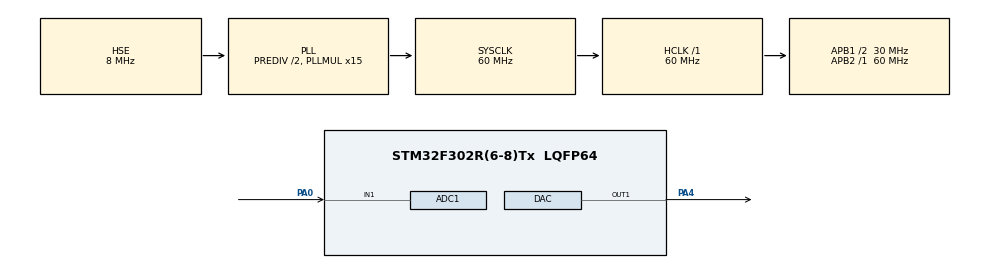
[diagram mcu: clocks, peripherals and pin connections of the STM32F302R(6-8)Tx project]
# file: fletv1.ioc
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ADC1.Channel-1\#ChannelRegularConversion=ADC_CHANNEL_1
ADC1.ClockPrescaler=ADC_CLOCK_ASYNC_DIV1
ADC1.ContinuousConvMode=ENABLE
ADC1.NbrOfConversionFlag=1
ADC1.Offset-1\#ChannelRegularConversion=0
ADC1.OffsetNumber-1\#ChannelRegularConversion=ADC_OFFSET_NONE
ADC1.Rank-1\#ChannelRegularConversion=1
ADC1.Resolution=ADC_RESOLUTION_10B
ADC1.SamplingTime-1\#ChannelRegularConversion=ADC_SAMPLETIME_1CYCLE_5
ADC1.SamplingTimeOPAMP-1\#ChannelRegularConversion=ADC_SAMPLETIME_61CYCLES_5
ADC1.master=1
DAC.DAC_Trigger=DAC_TRIGGER_T2_TRGO
Dma.DAC_CH1.0.Direction=DMA_MEMORY_TO_PERIPH
Dma.DAC_CH1.0.Instance=DMA1_Channel3
Dma.DAC_CH1.0.MemDataAlignment=DMA_MDATAALIGN_WORD
Dma.DAC_CH1.0.MemInc=DMA_MINC_ENABLE
Dma.DAC_CH1.0.Mode=DMA_CIRCULAR
Dma.DAC_CH1.0.PeriphDataAlignment=DMA_PDATAALIGN_WORD
Dma.DAC_CH1.0.PeriphInc=DMA_PINC_DISABLE
Dma.DAC_CH1.0.Priority=DMA_PRIORITY_LOW
Dma.Request0=DAC_CH1
Mcu.Family=STM32F3
Mcu.Name=STM32F302R(6-8)Tx
Mcu.Package=LQFP64
NVIC.ADC1_IRQn=true\:0\:0\:false\:false\:true\:true\:true\:true
NVIC.DMA1_Channel3_IRQn=true\:0\:0\:false\:false\:true\:false\:true\:true
NVIC.PriorityGroup=NVIC_PRIORITYGROUP_0
PA0.Mode=IN1-Single-Ended
PA0.Signal=ADC1_IN1
PA4.Signal=COMP_DAC1_group
PF0-OSC_IN.Mode=HSE-External-Oscillator
PF0-OSC_IN.Signal=RCC_OSC_IN
PF1-OSC_OUT.Mode=HSE-External-Oscillator
PF1-OSC_OUT.Signal=RCC_OSC_OUT
ProjectManager.HeapSize=0x200
ProjectManager.StackSize=0x400
ProjectManager.TargetToolchain=STM32CubeIDE
RCC.ADC12PRES=RCC_ADC1PLLCLK_DIV256
RCC.AHBFreq_Value=60000000
RCC.APB1CLKDivider=RCC_HCLK_DIV2
RCC.APB1Freq_Value=30000000
RCC.APB1TimFreq_Value=60000000
RCC.APB2Freq_Value=60000000
RCC.APB2TimFreq_Value=60000000
RCC.CortexFreq_Value=60000000
RCC.HCLKFreq_Value=60000000
RCC.HSE_VALUE=8000000
RCC.HSI_VALUE=8000000
RCC.PLLM=8
RCC.PLLMUL=RCC_PLL_MUL15
RCC.PLLN=336
RCC.PLLP=RCC_PLLP_DIV4
RCC.PLLQ=7
RCC.PLLSourceVirtual=RCC_PLLSOURCE_HSE
RCC.RCC_PLLsource_Clock_Source_FROM_HSE=RCC_HSE_PREDIV_DIV2
RCC.SYSCLKFreq_VALUE=60000000
RCC.SYSCLKSourceVirtual=RCC_SYSCLKSOURCE_PLLCLK
RCC.USBFreq_Value=60000000
SH.COMP_DAC1_group.0=DAC_OUT1,DAC_OUT1
TIM2.Period=1000-1
TIM2.Prescaler=3
TIM2.TIM_MasterOutputTrigger=TIM_TRGO_UPDATE
VP_TIM2_VS_ClockSourceINT.Mode=Internal
board=NUCLEO-F302R8

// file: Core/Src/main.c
/* USER CODE BEGIN Header */
/**
  ******************************************************************************
  * @file           : main.c
  * @brief          : Main program body
  ******************************************************************************
  * @attention
  *
  * Copyright (c) 2024 STMicroelectronics.
  * All rights reserved.
  *
  * This software is licensed under terms that can be found in the LICENSE file
  * in the root directory of this software component.
  * If no LICENSE file comes with this software, it is provided AS-IS.
  *
  ******************************************************************************
  */
/* USER CODE END Header */
#include "main.h"

/* USER CODE BEGIN Includes */
#include "math.h"
/* USER CODE END Includes */

/* USER CODE BEGIN PD */
#define PI 3.1415926
#define NUM_OF_SAMPLES 1000

/* USER CODE END PD */

ADC_HandleTypeDef hadc1;

DAC_HandleTypeDef hdac;
DMA_HandleTypeDef hdma_dac_ch1;

TIM_HandleTypeDef htim2;

void SystemClock_Config(void);
static void MX_GPIO_Init(void);
static void MX_DMA_Init(void);
static void MX_DAC_Init(void);
static void MX_TIM2_Init(void);
static void MX_ADC1_Init(void);

/* USER CODE BEGIN 0 */
uint32_t sine_val[NUM_OF_SAMPLES];
uint32_t adc_read;

void HAL_TIM_PeriodElapsedCallback(TIM_HandleTypeDef *htim){
// do something cool
}

void HAL_ADC_ConvCpltCallback(ADC_HandleTypeDef* adc_address){
	static int number_of_interrupts = 0;
	if(adc_address == &hadc1){
		if(number_of_interrupts == 12000){
			number_of_interrupts = 0;
			adc_read = HAL_ADC_GetValue(&hadc1);
			if(0 < adc_read && adc_read < 1000 - 1){
				TIM2->ARR = HAL_ADC_GetValue(&hadc1) - 1;
				TIM2->CNT = 0;
		}
			else if(adc_read == 0){
				TIM2->ARR = 1;
				TIM2->CNT = 0;
			}
			else{
				TIM2->ARR = 1000 - 1;
				TIM2->CNT = 0;
			}
		}

	}
	number_of_interrupts++;
}

void get_sine(){
	  for(int i = 0; i < NUM_OF_SAMPLES; i++){
		  sine_val[i] = (sin(i*2*PI/NUM_OF_SAMPLES) +1) * ((0xFFF + 1) / 2);

	  }
}

/* USER CODE END 0 */

int main(void)
{

  /* MCU Configuration--------------------------------------------------------*/

  /* Reset of all peripherals, Initializes the Flash interface and the Systick. */
  HAL_Init();

  /* Configure the system clock */
  SystemClock_Config();

  /* Initialize all configured peripherals */
  MX_GPIO_Init();
  MX_DMA_Init();
  MX_DAC_Init();
  MX_TIM2_Init();
  MX_ADC1_Init();
  /* USER CODE BEGIN 2 */

  get_sine();
  HAL_TIM_Base_Start(&htim2);
  HAL_DAC_Start_DMA(&hdac, DAC1_CHANNEL_1, sine_val, NUM_OF_SAMPLES, DAC_ALIGN_12B_R);
  HAL_ADC_Start_IT(&hadc1);

  /* USER CODE END 2 */

  /* Infinite loop */
  while (1)
  {

  }
}

void SystemClock_Config(void)
{
  RCC_OscInitTypeDef RCC_OscInitStruct = {0};
  RCC_ClkInitTypeDef RCC_ClkInitStruct = {0};
  RCC_PeriphCLKInitTypeDef PeriphClkInit = {0};

  /** Initializes the RCC Oscillators according to the specified parameters
  * in the RCC_OscInitTypeDef structure.
  */
  RCC_OscInitStruct.OscillatorType = RCC_OSCILLATORTYPE_HSE;
  RCC_OscInitStruct.HSEState = RCC_HSE_ON;
  RCC_OscInitStruct.HSEPredivValue = RCC_HSE_PREDIV_DIV2;
  RCC_OscInitStruct.HSIState = RCC_HSI_ON;
  RCC_OscInitStruct.PLL.PLLState = RCC_PLL_ON;
  RCC_OscInitStruct.PLL.PLLSource = RCC_PLLSOURCE_HSE;
  RCC_OscInitStruct.PLL.PLLMUL = RCC_PLL_MUL15;
  if (HAL_RCC_OscConfig(&RCC_OscInitStruct) != HAL_OK)
  {
    Error_Handler();
  }

  /** Initializes the CPU, AHB and APB buses clocks
  */
  RCC_ClkInitStruct.ClockType = RCC_CLOCKTYPE_HCLK|RCC_CLOCKTYPE_SYSCLK
                              |RCC_CLOCKTYPE_PCLK1|RCC_CLOCKTYPE_PCLK2;
  RCC_ClkInitStruct.SYSCLKSource = RCC_SYSCLKSOURCE_PLLCLK;
  RCC_ClkInitStruct.AHBCLKDivider = RCC_SYSCLK_DIV1;
  RCC_ClkInitStruct.APB1CLKDivider = RCC_HCLK_DIV2;
  RCC_ClkInitStruct.APB2CLKDivider = RCC_HCLK_DIV1;

  if (HAL_RCC_ClockConfig(&RCC_ClkInitStruct, FLASH_LATENCY_2) != HAL_OK)
  {
    Error_Handler();
  }
  PeriphClkInit.PeriphClockSelection = RCC_PERIPHCLK_ADC1;
  PeriphClkInit.Adc1ClockSelection = RCC_ADC1PLLCLK_DIV256;

  if (HAL_RCCEx_PeriphCLKConfig(&PeriphClkInit) != HAL_OK)
  {
    Error_Handler();
  }
}

static void MX_ADC1_Init(void)
{

  ADC_ChannelConfTypeDef sConfig = {0};

  /** Common config
  */
  hadc1.Instance = ADC1;
  hadc1.Init.ClockPrescaler = ADC_CLOCK_ASYNC_DIV1;
  hadc1.Init.Resolution = ADC_RESOLUTION_10B;
  hadc1.Init.ScanConvMode = ADC_SCAN_DISABLE;
  hadc1.Init.ContinuousConvMode = ENABLE;
  hadc1.Init.DiscontinuousConvMode = DISABLE;
  hadc1.Init.ExternalTrigConvEdge = ADC_EXTERNALTRIGCONVEDGE_NONE;
  hadc1.Init.ExternalTrigConv = ADC_SOFTWARE_START;
  hadc1.Init.DataAlign = ADC_DATAALIGN_RIGHT;
  hadc1.Init.NbrOfConversion = 1;
  hadc1.Init.DMAContinuousRequests = DISABLE;
  hadc1.Init.EOCSelection = ADC_EOC_SINGLE_CONV;
  hadc1.Init.LowPowerAutoWait = DISABLE;
  hadc1.Init.Overrun = ADC_OVR_DATA_OVERWRITTEN;
  if (HAL_ADC_Init(&hadc1) != HAL_OK)
  {
    Error_Handler();
  }

  /** Configure Regular Channel
  */
  sConfig.Channel = ADC_CHANNEL_1;
  sConfig.Rank = ADC_REGULAR_RANK_1;
  sConfig.SingleDiff = ADC_SINGLE_ENDED;
  sConfig.SamplingTime = ADC_SAMPLETIME_1CYCLE_5;
  sConfig.OffsetNumber = ADC_OFFSET_NONE;
  sConfig.Offset = 0;
  if (HAL_ADC_ConfigChannel(&hadc1, &sConfig) != HAL_OK)
  {
    Error_Handler();
  }

}

static void MX_DAC_Init(void)
{

  DAC_ChannelConfTypeDef sConfig = {0};

  /** DAC Initialization
  */
  hdac.Instance = DAC;
  if (HAL_DAC_Init(&hdac) != HAL_OK)
  {
    Error_Handler();
  }

  /** DAC channel OUT1 config
  */
  sConfig.DAC_Trigger = DAC_TRIGGER_T2_TRGO;
  sConfig.DAC_OutputBuffer = DAC_OUTPUTBUFFER_ENABLE;
  if (HAL_DAC_ConfigChannel(&hdac, &sConfig, DAC_CHANNEL_1) != HAL_OK)
  {
    Error_Handler();
  }

}

static void MX_TIM2_Init(void)
{

  TIM_ClockConfigTypeDef sClockSourceConfig = {0};
  TIM_MasterConfigTypeDef sMasterConfig = {0};

  htim2.Instance = TIM2;
  htim2.Init.Prescaler = 3;
  htim2.Init.CounterMode = TIM_COUNTERMODE_UP;
  htim2.Init.Period = 1000-1;
  htim2.Init.ClockDivision = TIM_CLOCKDIVISION_DIV1;
  htim2.Init.AutoReloadPreload = TIM_AUTORELOAD_PRELOAD_DISABLE;
  if (HAL_TIM_Base_Init(&htim2) != HAL_OK)
  {
    Error_Handler();
  }
  sClockSourceConfig.ClockSource = TIM_CLOCKSOURCE_INTERNAL;
  if (HAL_TIM_ConfigClockSource(&htim2, &sClockSourceConfig) != HAL_OK)
  {
    Error_Handler();
  }
  sMasterConfig.MasterOutputTrigger = TIM_TRGO_UPDATE;
  sMasterConfig.MasterSlaveMode = TIM_MASTERSLAVEMODE_DISABLE;
  if (HAL_TIMEx_MasterConfigSynchronization(&htim2, &sMasterConfig) != HAL_OK)
  {
    Error_Handler();
  }

}

static void MX_DMA_Init(void)
{

  /* DMA controller clock enable */
  __HAL_RCC_DMA1_CLK_ENABLE();

  /* DMA interrupt init */
  /* DMA1_Channel3_IRQn interrupt configuration */
  HAL_NVIC_SetPriority(DMA1_Channel3_IRQn, 0, 0);
  HAL_NVIC_EnableIRQ(DMA1_Channel3_IRQn);

}

static void MX_GPIO_Init(void)
{

  /* GPIO Ports Clock Enable */
  __HAL_RCC_GPIOF_CLK_ENABLE();
  __HAL_RCC_GPIOA_CLK_ENABLE();

}

void Error_Handler(void)
{
  __disable_irq();
  while (1)
  {
  }
}
